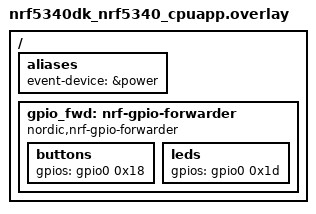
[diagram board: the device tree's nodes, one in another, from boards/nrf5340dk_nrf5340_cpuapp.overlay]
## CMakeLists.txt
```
# Copyright (c) 2025 Nordic Semiconductor ASA
# SPDX-License-Identifier: Apache-2.0

cmake_minimum_required(VERSION 3.20.0)

find_package(Zephyr REQUIRED HINTS $ENV{ZEPHYR_BASE})
project(pm_event_device)

target_sources(app PRIVATE src/main.c)
```

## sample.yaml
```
# Copyright (c) 2025 Nordic Semiconductor ASA
# SPDX-License-Identifier: Apache-2.0

sample:
  name: PM event device sample
tests:
  sample.subsys.pm.event_device:
    tags:
      - pm_event_device
    platform_allow:
      - nrf54h20dk/nrf54h20/cpuapp
      - nrf54l15dk/nrf54l15/cpuapp
      - nrf5340dk/nrf5340/cpuapp
      - nrf5340dk/nrf5340/cpunet
      - nrf52840dk/nrf52840
```

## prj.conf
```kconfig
# Copyright (c) 2025 Nordic Semiconductor ASA
# SPDX-License-Identifier: Apache-2.0

CONFIG_PM_EVENT_DEVICE=y
```

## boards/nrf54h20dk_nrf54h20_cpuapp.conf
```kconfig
# Copyright (c) 2025 Nordic Semiconductor ASA
# SPDX-License-Identifier: Apache-2.0

# PM is required for the CPU to enter inactive state
# allowing for LRCCONF CONSTLAT to have measurable
# impact on current consumption.
CONFIG_PM=y
```

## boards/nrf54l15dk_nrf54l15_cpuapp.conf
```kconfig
# Copyright (c) 2025 Nordic Semiconductor ASA
# SPDX-License-Identifier: Apache-2.0

# The RRAM event device is a flash device. This selection
# includes the device driver for it.
CONFIG_FLASH=y
```

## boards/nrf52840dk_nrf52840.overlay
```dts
/*
 * Copyright (c) 2025 Nordic Semiconductor ASA
 *
 * SPDX-License-Identifier: Apache-2.0
 */

 / {
	aliases {
		event-device = &power;
	};
};
```

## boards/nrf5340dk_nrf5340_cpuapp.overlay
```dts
/*
 * Copyright (c) 2025 Nordic Semiconductor ASA
 *
 * SPDX-License-Identifier: Apache-2.0
 */

/ {
	aliases {
		event-device = &power;
	};

	gpio_fwd: nrf-gpio-forwarder {
		compatible = "nordic,nrf-gpio-forwarder";
		status = "okay";

		buttons {
			gpios = <&gpio0 0x18 0>;
		};

		leds {
			gpios = <&gpio0 0x1d 0>;
		};
	};
};
```

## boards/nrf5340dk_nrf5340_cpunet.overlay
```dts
/*
 * Copyright (c) 2025 Nordic Semiconductor ASA
 *
 * SPDX-License-Identifier: Apache-2.0
 */

/ {
	aliases {
		event-device = &power;
	};
};
```

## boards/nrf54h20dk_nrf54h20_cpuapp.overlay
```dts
/*
 * Copyright (c) 2025 Nordic Semiconductor ASA
 *
 * SPDX-License-Identifier: Apache-2.0
 */

/ {
	aliases {
		event-device = &cpuapp_lrcconf;
	};
};
```

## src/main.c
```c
/*
 * Copyright (c) 2025 Nordic Semiconductor ASA
 *
 * SPDX-License-Identifier: Apache-2.0
 */

#include <zephyr/kernel.h>
#include <zephyr/pm/event_device.h>

#define SAMPLE_EVENT_DEVICE_NODE DT_ALIAS(event_device)
#define SAMPLE_EVENT_DEVICE      PM_EVENT_DEVICE_DT_GET(SAMPLE_EVENT_DEVICE_NODE)
#define SAMPLE_TIMEOUT           K_SECONDS(10)

static const struct pm_event_device *sample_event_device = SAMPLE_EVENT_DEVICE;

int main(void)
{
	uint32_t max_event_state;
	const char *dev_name;
	struct pm_event_device_event event;
	int64_t effective_uptime_ticks;

	max_event_state = pm_event_device_get_max_event_state(sample_event_device);
	dev_name = pm_event_device_get_dev(sample_event_device)->name;

	while (1) {
		printk("requesting event state %u for %s\n", max_event_state, dev_name);
		effective_uptime_ticks = pm_event_device_request_event(sample_event_device,
								       &event,
								       max_event_state);

		printk("wait until event state is effective\n");
		k_sleep(K_TIMEOUT_ABS_TICKS(effective_uptime_ticks));
		printk("event state is effective\n");
		k_sleep(SAMPLE_TIMEOUT);

		printk("releasing event state %u for %s\n", max_event_state, dev_name);
		pm_event_device_release_event(&event);
		k_sleep(SAMPLE_TIMEOUT);
	}

	return 0;
}
```
